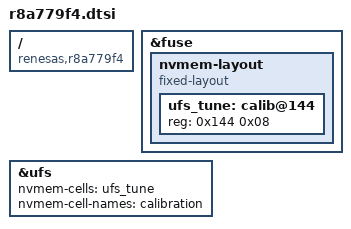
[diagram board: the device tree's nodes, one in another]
// SPDX-License-Identifier: (GPL-2.0 OR MIT)
/*
 * Device Tree Source for the R-Car S4-8 (R8A779F4) SoC
 *
 * Copyright (C) 2023 Renesas Electronics Corp.
 */

#include "r8a779f0.dtsi"

/ {
	compatible = "renesas,r8a779f4", "renesas,r8a779f0";
};

&fuse {
	nvmem-layout {
		compatible = "fixed-layout";
		#address-cells = <1>;
		#size-cells = <1>;

		ufs_tune: calib@144 {
			reg = <0x144 0x08>;
		};
	};
};

&ufs {
	nvmem-cells = <&ufs_tune>;
	nvmem-cell-names = "calibration";
};
